VERSION ""

NS_ :

BS_:

BU_: CBS FRBE PDM CBM DMU DEC

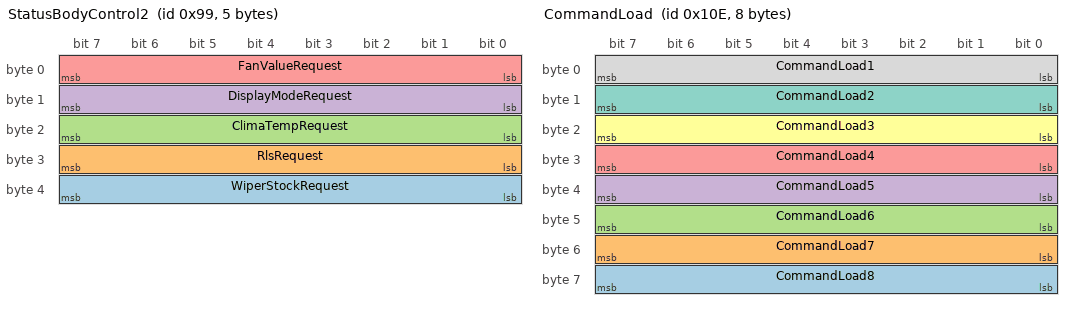
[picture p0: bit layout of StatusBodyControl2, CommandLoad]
BO_ 153 StatusBodyControl2: 5 DEC
 SG_ WiperStockRequest : 32|8@1+ (1,0) [0|255] "" Vector__XXX
 SG_ RlsRequest : 24|8@1+ (1,0) [0|255] ""  DMU
 SG_ ClimaTempRequest : 16|8@1+ (1,0) [0|255] ""  DMU,CBM
 SG_ DisplayModeRequest : 8|8@1+ (1,0) [0|255] ""  DMU
 SG_ FanValueRequest : 0|8@1+ (1,0) [0|255] ""  DMU,CBM

BO_ 271 DataRecorder: 3 DEC
 SG_ DcyStatus : 16|8@1+ (1,0) [0|255] "" Vector__XXX
 SG_ VBat : 8|8@1+ (1,0) [0|255] ""  DMU

BO_ 270 CommandLoad: 8 DEC
 SG_ CommandLoad8 : 56|8@1+ (1,0) [0|255] ""  PDM
 SG_ CommandLoad7 : 48|8@1+ (1,0) [0|255] ""  PDM
 SG_ CommandLoad6 : 40|8@1+ (1,0) [0|255] ""  PDM
 SG_ CommandLoad5 : 32|8@1+ (1,0) [0|255] ""  PDM
 SG_ CommandLoad4 : 24|8@1+ (1,0) [0|255] ""  PDM
 SG_ CommandLoad3 : 16|8@1+ (1,0) [0|255] ""  PDM
 SG_ CommandLoad2 : 8|8@1+ (1,0) [0|255] ""  PDM
 SG_ CommandLoad1 : 0|8@1+ (1,0) [0|255] ""  PDM

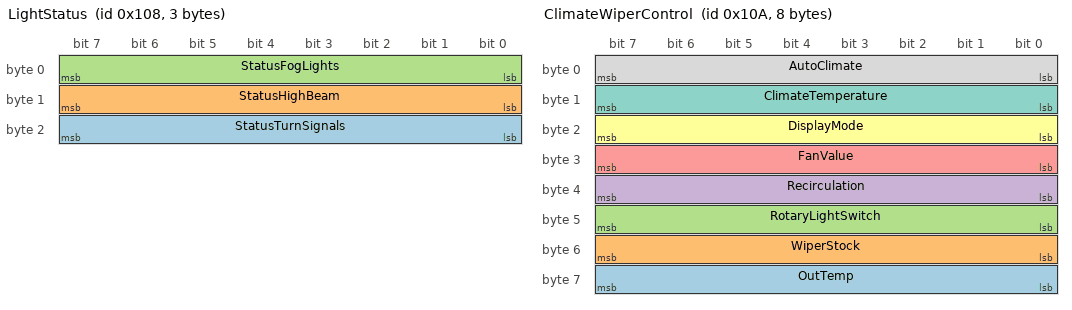
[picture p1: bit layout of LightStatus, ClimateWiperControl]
BO_ 264 LightStatus: 3 FRBE
 SG_ StatusTurnSignals : 16|8@1+ (1,0) [0|255] ""  DEC
 SG_ StatusHighBeam : 8|8@1+ (1,0) [0|255] ""  DEC
 SG_ StatusFogLights : 0|8@1+ (1,0) [0|255] ""  DEC

BO_ 266 ClimateWiperControl: 8 CBS
 SG_ OutTemp : 56|8@1+ (1,0) [0|255] "" Vector__XXX
 SG_ WiperStock : 48|8@1+ (1,0) [0|255] ""  DEC
 SG_ RotaryLightSwitch : 40|8@1+ (1,0) [0|255] ""  DEC
 SG_ Recirculation : 32|8@1+ (1,0) [0|255] ""  DEC
 SG_ FanValue : 24|8@1+ (1,0) [0|255] ""  DEC
 SG_ DisplayMode : 16|8@1+ (1,0) [0|255] ""  DEC
 SG_ ClimateTemperature : 8|8@1+ (1,0) [0|255] ""  DEC
 SG_ AutoClimate : 0|8@1+ (1,0) [0|255] ""  DEC

BO_ 269 StatusErrorSetting_705: 1 PDM
 SG_ Err705_ID : 0|8@1+ (1,0) [0|255] ""  DEC

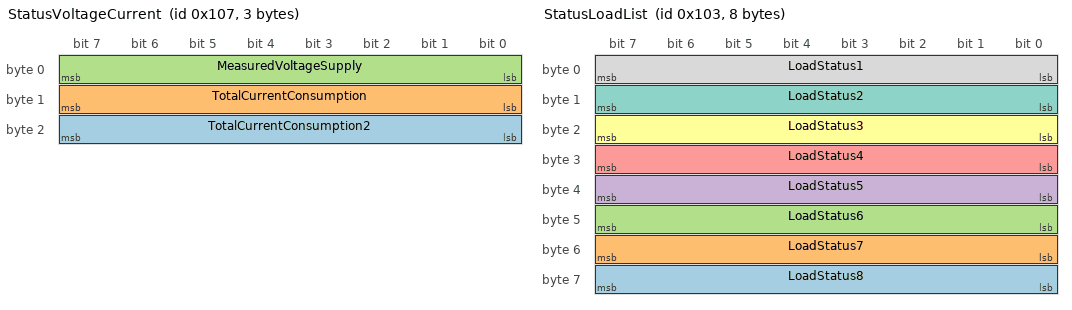
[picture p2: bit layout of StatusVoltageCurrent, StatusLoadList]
BO_ 263 StatusVoltageCurrent: 3 PDM
 SG_ TotalCurrentConsumption2 : 16|8@1+ (1,0) [0|255] ""  DEC
 SG_ TotalCurrentConsumption : 8|8@1+ (1,0) [0|255] ""  DEC
 SG_ MeasuredVoltageSupply : 0|8@1+ (1,0) [0|255] ""  DEC

BO_ 260 StatusPowerSupplyNetwork: 1 PDM
 SG_ PSNWarn : 0|8@1+ (1,0) [0|255] ""  DEC

BO_ 259 StatusLoadList: 8 PDM
 SG_ LoadStatus8 : 56|8@1+ (1,0) [0|255] ""  DEC
 SG_ LoadStatus7 : 48|8@1+ (1,0) [0|255] ""  DEC
 SG_ LoadStatus6 : 40|8@1+ (1,0) [0|255] ""  DEC
 SG_ LoadStatus5 : 32|8@1+ (1,0) [0|255] ""  DEC
 SG_ LoadStatus4 : 24|8@1+ (1,0) [0|255] ""  DEC
 SG_ LoadStatus3 : 16|8@1+ (1,0) [0|255] ""  DEC
 SG_ LoadStatus2 : 8|8@1+ (1,0) [0|255] ""  DEC
 SG_ LoadStatus1 : 0|8@1+ (1,0) [0|255] ""  DEC

BO_ 267 InfoClustermessage: 1 DEC
 SG_ ICM_ID : 0|8@1+ (1,0) [0|255] ""  DMU

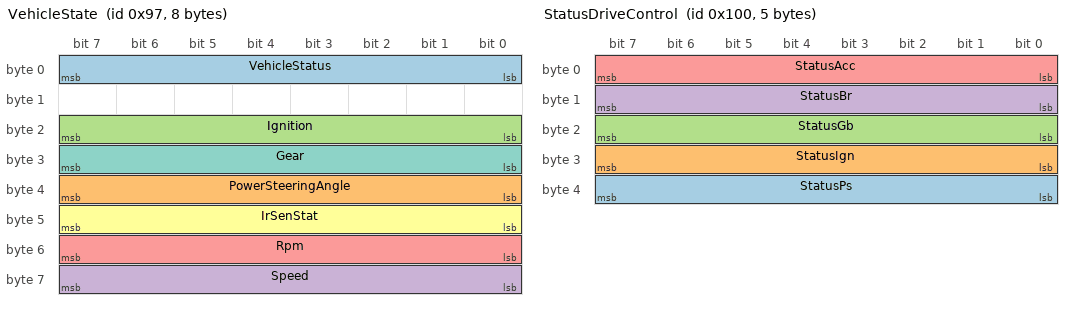
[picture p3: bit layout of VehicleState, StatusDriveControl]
BO_ 151 VehicleState: 8 DEC
 SG_ VehicleStatus : 0|8@1+ (1,0) [0|255] "" Vector__XXX
 SG_ PowerSteeringAngle : 32|8@1+ (1,0) [0|255] ""  DMU
 SG_ Ignition : 16|8@1+ (1,0) [0|255] ""  DMU
 SG_ Speed : 56|8@1+ (1,0) [0|255] ""  CBM,DMU
 SG_ Rpm : 48|8@1+ (1,0) [0|255] ""  DMU
 SG_ IrSenStat : 40|8@1+ (1,0) [0|255] ""  DMU
 SG_ Gear : 24|8@1+ (1,0) [0|255] ""  DMU

BO_ 268 StatusErrorSetting_701: 1 CBM
 SG_ Err701_ID : 0|8@1+ (1,0) [0|255] ""  DEC

BO_ 256 StatusDriveControl: 5 CBM
 SG_ StatusPs : 32|8@1+ (1,0) [0|255] ""  DEC
 SG_ StatusIgn : 24|8@1+ (1,0) [0|255] ""  DEC
 SG_ StatusGb : 16|8@1+ (1,0) [0|255] ""  DEC
 SG_ StatusBr : 8|8@1+ (1,0) [0|255] ""  DEC
 SG_ StatusAcc : 0|8@1+ (1,0) [0|255] ""  DEC

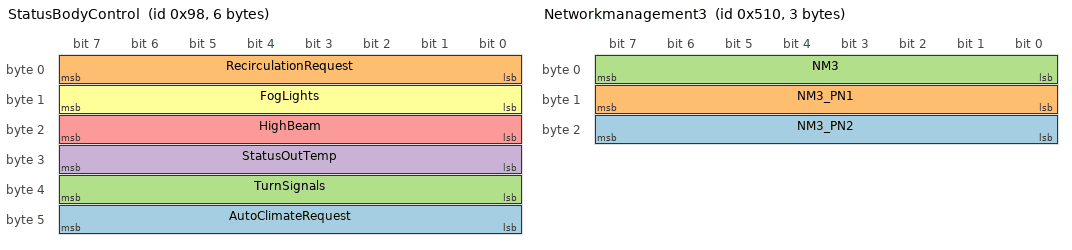
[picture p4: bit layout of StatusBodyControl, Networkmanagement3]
BO_ 152 StatusBodyControl: 6 DEC
 SG_ AutoClimateRequest : 40|8@1+ (1,0) [0|255] ""  DMU,CBM
 SG_ RecirculationRequest : 0|8@1+ (1,0) [0|255] ""  DMU,CBM
 SG_ TurnSignals : 32|8@1+ (1,0) [0|255] ""  DMU
 SG_ StatusOutTemp : 24|8@1+ (1,0) [0|255] ""  CBM,DMU
 SG_ HighBeam : 16|8@1+ (1,0) [0|255] ""  DMU
 SG_ FogLights : 8|8@1+ (1,0) [0|255] ""  DMU

BO_ 257 StatusActuator: 2 CBM
 SG_ StatusDoorRight : 8|8@1+ (1,0) [0|255] ""  DEC
 SG_ StatusDoorLeft : 0|8@1+ (1,0) [0|255] ""  DEC

BO_ 1541 XCP_Response_605: 8 PDM

BO_ 1539 XCP_Response_603: 8 DMU

BO_ 1537 XCP_Response_601: 8 CBM

BO_ 1535 XCP_Response_MasterRequest: 8 DEC

BO_ 1534 XCP_Request_MasterRequest: 8 Vector__XXX

BO_ 1540 XCP_Request_604: 8 DEC

BO_ 1538 XCP_Request_602: 8 DEC

BO_ 1536 XCP_Request_600: 8 DEC

BO_ 1797 DiagCAN_Response_705: 8 PDM

BO_ 1795 DiagCAN_Response_703: 8 DMU

BO_ 1793 DiagCAN_Response_701: 8 CBM

BO_ 1791 DiagCAN_Response_DiagMaster: 8 DEC

BO_ 1790 DiagCAN_Request_DiagMaster: 8 Vector__XXX

BO_ 1796 DiagCAN_Request_704: 8 DEC

BO_ 1794 DiagCAN_Request_702: 8 DEC

BO_ 1792 DiagCAN_Request_700: 8 DEC

BO_ 1296 Networkmanagement3: 3 DEC
 SG_ NM3_PN2 : 16|8@1- (1,0) [0|0] ""  DMU
 SG_ NM3_PN1 : 8|8@1+ (1,0) [0|255] ""  CBM
 SG_ NM3 : 0|8@1+ (1,0) [0|255] ""  PDM,DMU,CBM

BA_DEF_  "BusType" STRING ;
BA_DEF_DEF_  "BusType" "CAN";
